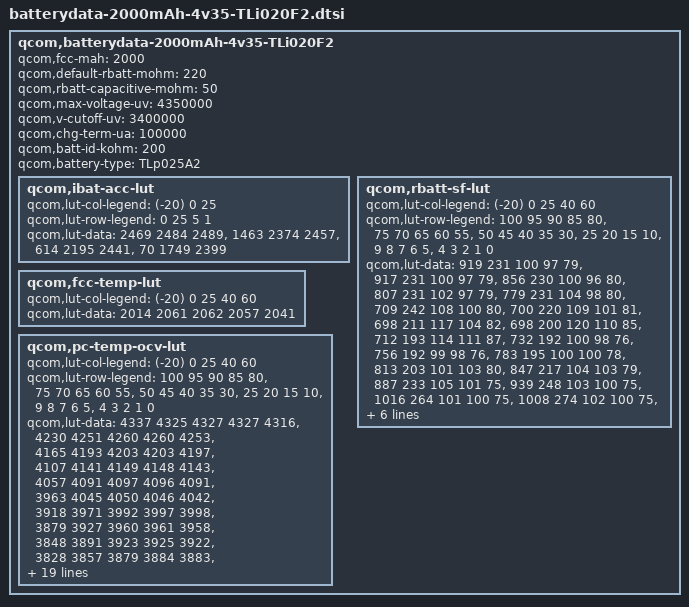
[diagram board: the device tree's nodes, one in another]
 qcom,batterydata-2000mAh-4v35-TLi020F2 {
	qcom,fcc-mah = <2000>;
	qcom,default-rbatt-mohm = <220>;
	qcom,rbatt-capacitive-mohm = <50>;
	qcom,max-voltage-uv = <4350000>;
	qcom,v-cutoff-uv = <3400000>;
	qcom,chg-term-ua = <100000>;
	qcom,batt-id-kohm = <200>;
	qcom,battery-type = "TLp025A2";

	qcom,ibat-acc-lut {
		qcom,lut-col-legend = <(-20) 0 25>;
		qcom,lut-row-legend = <0 25 5 1>;
		qcom,lut-data = <2469 2484 2489>,
				<1463 2374 2457>,
				<614 2195 2441>,
				<70 1749 2399>;
	};

	qcom,rbatt-sf-lut {
		qcom,lut-col-legend = <(-20) 0 25 40 60>;
		qcom,lut-row-legend = <100 95 90 85 80>,
				<75 70 65 60 55>,
				<50 45 40 35 30>,
				<25 20 15 10>,
				<9 8 7 6 5>,
				<4 3 2 1 0>;
		qcom,lut-data = <919 231 100 97 79>, 
				<917 231 100 97 79>, 
				<856 230 100 96 80>, 
				<807 231 102 97 79>, 
				<779 231 104 98 80>, 
				<709 242 108 100 80>, 
				<700 220 109 101 81>, 
				<698 211 117 104 82>, 
				<698 200 120 110 85>, 
				<712 193 114 111 87>, 
				<732 192 100 98 76>, 
				<756 192 99 98 76>, 
				<783 195 100 100 78>, 
				<813 203 101 103 80>, 
				<847 217 104 103 79>, 
				<887 233 105 101 75>, 
				<939 248 103 100 75>, 
				<1016 264 101 100 75>, 
				<1008 274 102 100 75>, 
				<1046 284 105 100 76>, 
				<1089 299 108 102 78>, 
				<1178 316 111 104 80>, 
				<1328 337 116 106 83>, 
				<1523 361 119 107 80>, 
				<1811 378 114 103 78>, 
				<2278 414 118 105 80>, 
				<3124 486 128 112 88>, 
				<11401 4680 2379 133 641>, 
				<186281 236746 116787 88716 31945>;
	};

	qcom,fcc-temp-lut {
		qcom,lut-col-legend = <(-20) 0 25 40 60>;
		qcom,lut-data = <2014 2061 2062 2057 2041>;
	};

	qcom,pc-temp-ocv-lut {
		qcom,lut-col-legend = <(-20) 0 25 40 60>;
		qcom,lut-row-legend = <100 95 90 85 80>,
				<75 70 65 60 55>,
				<50 45 40 35 30>,
				<25 20 15 10>,
				<9 8 7 6 5>,
				<4 3 2 1 0>;
		qcom,lut-data = <4337 4325 4327 4327 4316>,
				<4230 4251 4260 4260 4253>,
				<4165 4193 4203 4203 4197>,
				<4107 4141 4149 4148 4143>,
				<4057 4091 4097 4096 4091>,
				<3963 4045 4050 4046 4042>,
				<3918 3971 3992 3997 3998>,
				<3879 3927 3960 3961 3958>,
				<3848 3891 3923 3925 3922>,
				<3828 3857 3879 3884 3883>,
				<3814 3830 3837 3838 3837>,
				<3801 3808 3813 3814 3813>,
				<3787 3791 3796 3796 3795>,
				<3774 3781 3782 3782 3780>,
				<3760 3774 3772 3768 3764>,
				<3746 3764 3763 3755 3741>,
				<3732 3745 3745 3736 3720>,
				<3716 3716 3710 3703 3691>,
				<3693 3695 3687 3680 3667>,
				<3686 3692 3686 3679 3667>,
				<3678 3690 3685 3678 3666>,
				<3668 3687 3684 3676 3664>,
				<3656 3683 3682 3674 3661>,
				<3635 3672 3672 3662 3646>,
				<3604 3637 3635 3625 3603>,
				<3558 3575 3574 3566 3542>,
				<3486 3486 3490 3486 3462>,
				<3362 3342 3359 3367 3337>,
				<3000 3000 3000 3000 3000>;
	};
};
